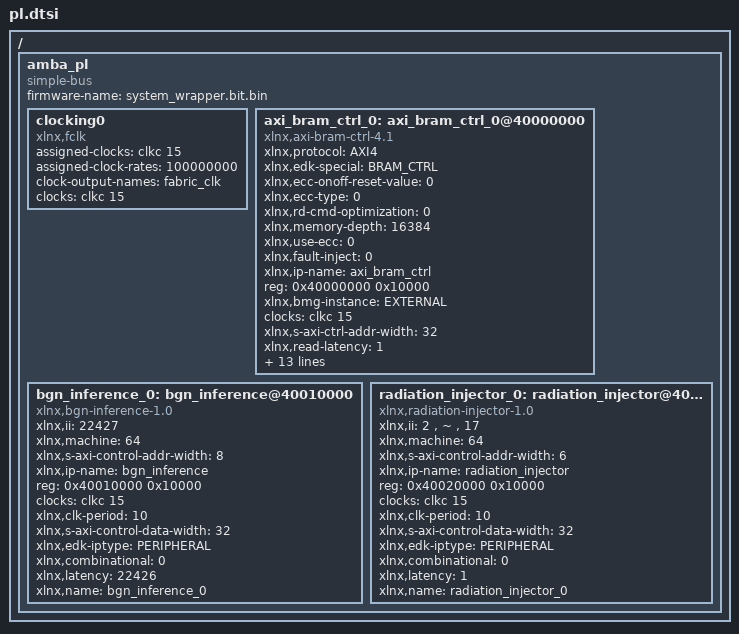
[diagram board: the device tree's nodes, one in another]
/ {
	amba_pl: amba_pl {
		ranges;
		compatible = "simple-bus";
		#address-cells = <1>;
		#size-cells = <1>;
		firmware-name = "system_wrapper.bit.bin";
		clocking0: clocking0 {
			compatible = "xlnx,fclk";
			assigned-clocks = <&clkc 15>;
			assigned-clock-rates = <100000000>;
			#clock-cells = <0>;
			clock-output-names = "fabric_clk";
			clocks = <&clkc 15>;
		};
		axi_bram_ctrl_0: axi_bram_ctrl_0@40000000 {
			xlnx,protocol = "AXI4";
			xlnx,edk-special = "BRAM_CTRL";
			compatible = "xlnx,axi-bram-ctrl-4.1" , "xlnx,axi-bram-ctrl";
			xlnx,ecc-onoff-reset-value = <0>;
			xlnx,ecc-type = <0>;
			xlnx,rd-cmd-optimization = <0>;
			xlnx,memory-depth = <16384>;
			xlnx,use-ecc = <0>;
			xlnx,fault-inject = <0>;
			xlnx,ip-name = "axi_bram_ctrl";
			reg = <0x40000000 0x10000>;
			xlnx,bmg-instance = "EXTERNAL";
			clocks = <&clkc 15>;
			xlnx,s-axi-ctrl-addr-width = <32>;
			xlnx,read-latency = <1>;
			xlnx,id-width = <0>;
			xlnx,s-axi-supports-narrow-burst = <0>;
			xlnx,supports-narrow-burst = <0>;
			xlnx,single-port-bram = <1>;
			xlnx,ecc = <0>;
			xlnx,edk-iptype = "PERIPHERAL";
			status = "okay";
			clock-names = "s_axi_aclk";
			xlnx,data-width = <32>;
			xlnx,bram-addr-width = <14>;
			xlnx,bram-inst-mode = "EXTERNAL";
			xlnx,s-axi-ctrl-data-width = <32>;
			xlnx,mem-depth = <16384>;
			xlnx,s-axi-id-width = <1>;
			xlnx,name = "axi_bram_ctrl_0";
		};
		bgn_inference_0: bgn_inference@40010000 {
			compatible = "xlnx,bgn-inference-1.0";
			xlnx,ii = <22427>;
			xlnx,machine = <64>;
			xlnx,s-axi-control-addr-width = <8>;
			xlnx,ip-name = "bgn_inference";
			reg = <0x40010000 0x10000>;
			clocks = <&clkc 15>;
			xlnx,clk-period = <10>;
			xlnx,s-axi-control-data-width = <32>;
			xlnx,edk-iptype = "PERIPHERAL";
			status = "okay";
			clock-names = "ap_clk";
			xlnx,combinational = <0>;
			xlnx,latency = <22426>;
			xlnx,name = "bgn_inference_0";
		};
		radiation_injector_0: radiation_injector@40020000 {
			compatible = "xlnx,radiation-injector-1.0";
			xlnx,ii = "2 , ~ , 17";
			xlnx,machine = <64>;
			xlnx,s-axi-control-addr-width = <6>;
			xlnx,ip-name = "radiation_injector";
			reg = <0x40020000 0x10000>;
			clocks = <&clkc 15>;
			xlnx,clk-period = <10>;
			xlnx,s-axi-control-data-width = <32>;
			xlnx,edk-iptype = "PERIPHERAL";
			status = "okay";
			clock-names = "ap_clk";
			xlnx,combinational = <0>;
			xlnx,latency = <1>;
			xlnx,name = "radiation_injector_0";
		};
	};
};
